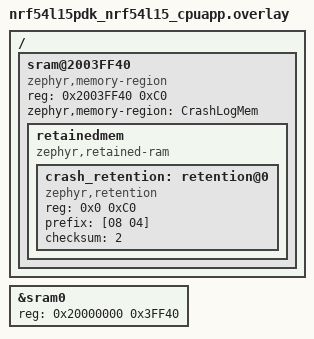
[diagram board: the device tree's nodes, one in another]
/* Copyright (c) 2024 Nordic Semiconductor ASA
 *
 * SPDX-License-Identifier: LicenseRef-Nordic-5-Clause
 */

/ {
	sram@2003FF40 {
		compatible = "zephyr,memory-region", "mmio-sram";
		reg = <0x2003FF40 0xC0>;
		zephyr,memory-region = "CrashLogMem";
		status = "okay";
		retainedmem {
			compatible = "zephyr,retained-ram";
			status = "okay";
			#address-cells = <1>;
			#size-cells = <1>;
			crash_retention: retention@0 {
					compatible = "zephyr,retention";
					status = "okay";
					reg = <0x0 0xC0>;
					prefix = [08 04];
					checksum = <2>;
			};
		};
	};
};

/* Reduce SRAM0 usage by 192B to account for non-init area */
&sram0 {
	reg = <0x20000000 0x3FF40>;
};
